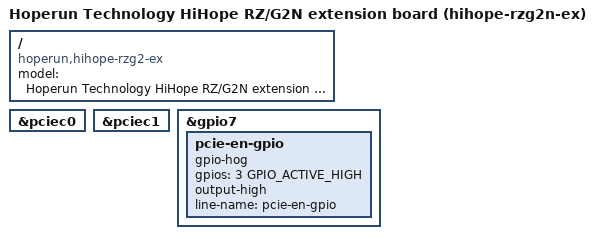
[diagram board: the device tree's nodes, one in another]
// SPDX-License-Identifier: GPL-2.0
/*
 * Device Tree Source for the Hoperun Technology HiHope RZ/G2N extension board
 * (hihope-rzg2n-ex)
 *
 * Copyright (C) 2019 Renesas Electronics Corp.
 */

#include "r8a774b1-hihope-rzg2n.dts"
#include "hihope-rzg2-ex.dtsi"
#include <dt-bindings/gpio/gpio.h>

/ {
	model = "Hoperun Technology HiHope RZ/G2N extension board \
		(hihope-rzg2n-ex)";
	compatible =	"hoperun,hihope-rzg2-ex", "hoperun,hihope-rzg2n",
			"renesas,r8a774b1";
};

&pciec0 {
	status = "okay";
};

&pciec1 {
	status = "okay";
};

&gpio7 {
	pcie-en-gpio {
		gpio-hog;
		gpios = <3 GPIO_ACTIVE_HIGH>;
		output-high;
		line-name = "pcie-en-gpio";
	};
};
